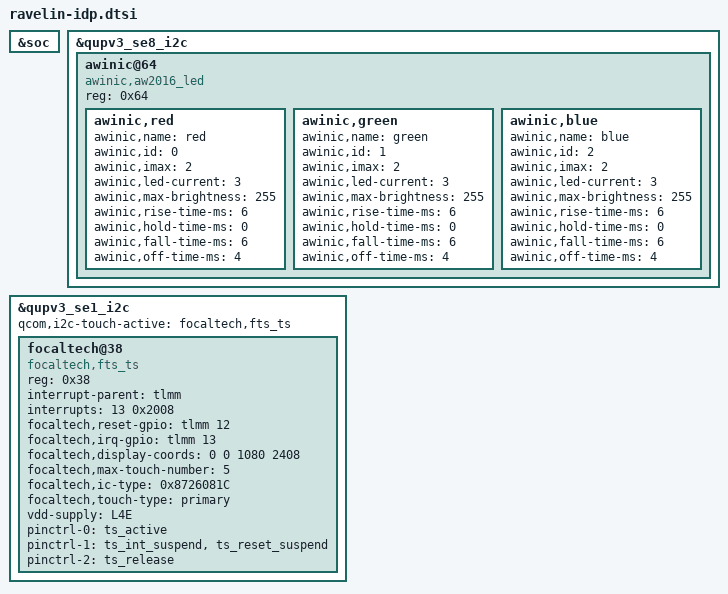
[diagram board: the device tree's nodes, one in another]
#include "ravelin-pmic-overlay.dtsi"
#include "ravelin-pm7250b.dtsi"

&soc {
};

&qupv3_se8_i2c {
	awinic@64 {
		compatible = "awinic,aw2016_led";
		reg = <0x64>;

		awinic,red {
			awinic,name = "red";
			awinic,id = <0>;
			awinic,imax = <2>;
			awinic,led-current = <3>;
			awinic,max-brightness = <255>;
			awinic,rise-time-ms = <6>;
			awinic,hold-time-ms = <0>;
			awinic,fall-time-ms = <6>;
			awinic,off-time-ms = <4>;
		};

		awinic,green {
			awinic,name = "green";
			awinic,id = <1>;
			awinic,imax = <2>;
			awinic,led-current = <3>;
			awinic,max-brightness = <255>;
			awinic,rise-time-ms = <6>;
			awinic,hold-time-ms = <0>;
			awinic,fall-time-ms = <6>;
			awinic,off-time-ms = <4>;
		};

		awinic,blue {
			awinic,name = "blue";
			awinic,id = <2>;
			awinic,imax = <2>;
			awinic,led-current = <3>;
			awinic,max-brightness = <255>;
			awinic,rise-time-ms = <6>;
			awinic,hold-time-ms = <0>;
			awinic,fall-time-ms = <6>;
			awinic,off-time-ms = <4>;
		};
	};
};

&qupv3_se1_i2c {
	#address-cells = <1>;
	#size-cells = <0>;

	status = "ok";
	qcom,i2c-touch-active = "focaltech,fts_ts";

	focaltech@38 {
		compatible = "focaltech,fts_ts";
		reg = <0x38>;

		interrupt-parent = <&tlmm>;
		interrupts = <13 0x2008>;
		focaltech,reset-gpio = <&tlmm 12 0x00>;
		focaltech,irq-gpio = <&tlmm 13 0x2008>;
		focaltech,display-coords = <0 0 1080 2408>;
		focaltech,max-touch-number = <5>;
		focaltech,ic-type = <0x8726081C>;
		focaltech,touch-type = "primary";

		vdd-supply = <&L4E>;

		pinctrl-names = "pmx_ts_active","pmx_ts_suspend","pmx_ts_release";
		pinctrl-0 = <&ts_active>;
		pinctrl-1 = <&ts_int_suspend &ts_reset_suspend>;
		pinctrl-2 = <&ts_release>;
	};
};
